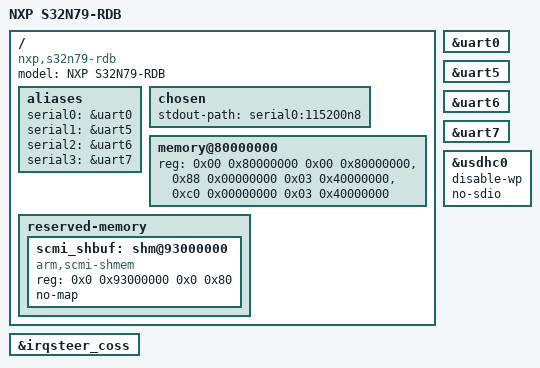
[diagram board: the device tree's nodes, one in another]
// SPDX-License-Identifier: (GPL-2.0+ OR BSD-3-Clause)
/*
 * Copyright 2026 NXP
 *
 * NXP S32N79 Reference Design Board (S32N79-RDB)
 */

/dts-v1/;
#include "s32n79.dtsi"

/ {
	model = "NXP S32N79-RDB";
	compatible = "nxp,s32n79-rdb", "nxp,s32n79";

	aliases {
		serial0 = &uart0;
		serial1 = &uart5;
		serial2 = &uart6;
		serial3 = &uart7;
	};

	chosen {
		stdout-path = "serial0:115200n8";
	};

	memory@80000000 {
		device_type = "memory";
		reg = <0x00 0x80000000 0x00 0x80000000>,
			<0x88 0x00000000 0x03 0x40000000>,
			<0xc0 0x00000000 0x03 0x40000000>;
	};

	reserved-memory {
		#address-cells = <2>;
		#size-cells = <2>;
		ranges;

		scmi_shbuf: shm@93000000 {
			compatible = "arm,scmi-shmem";
			reg = <0x0 0x93000000 0x0 0x80>;
			no-map;
		};
	};
};

&irqsteer_coss {
	status = "okay";
};

&uart0 {
	status = "okay";
};

&uart5 {
	status = "okay";
};

&uart6 {
	status = "okay";
};

&uart7 {
	status = "okay";
};

&usdhc0 {
	disable-wp;
	no-sdio;
	status = "okay";
};
